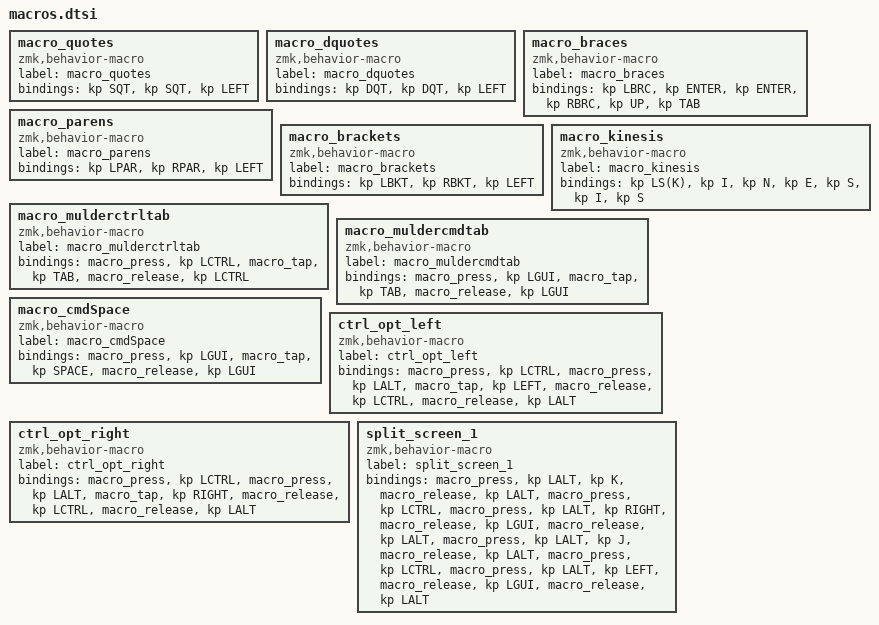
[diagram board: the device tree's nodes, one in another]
  macro_quotes: macro_quotes {
    compatible = "zmk,behavior-macro";
    label = "macro_quotes";
    #binding-cells = <0>;
    bindings = <&kp SQT>, <&kp SQT>, <&kp LEFT>;
  };
  macro_dquotes: macro_dquotes {
    compatible = "zmk,behavior-macro";
    label = "macro_dquotes";
    #binding-cells = <0>;
    bindings = <&kp DQT>, <&kp DQT>, <&kp LEFT>;
  };
  macro_braces: macro_braces {
    compatible = "zmk,behavior-macro";
    label = "macro_braces";
    #binding-cells = <0>;
    bindings = <&kp LBRC>, <&kp ENTER>, <&kp ENTER>, <&kp RBRC>, <&kp UP>, <&kp TAB>;
  };
  macro_parens: macro_parens {
    compatible = "zmk,behavior-macro";
    label = "macro_parens";
    #binding-cells = <0>;
    bindings = <&kp LPAR>, <&kp RPAR>, <&kp LEFT>;
  };
  macro_brackets: macro_brackets {
    compatible = "zmk,behavior-macro";
    label = "macro_brackets";
    #binding-cells = <0>;
    bindings = <&kp LBKT>, <&kp RBKT>, <&kp LEFT>;
  };
  macro_kinesis: macro_kinesis {
    compatible = "zmk,behavior-macro";
    label = "macro_kinesis";
    #binding-cells = <0>;
    bindings = <&kp LS(K)>, <&kp I>, <&kp N>, <&kp E>, <&kp S>, <&kp I>, <&kp S>;
  };
  macro_mulderctrltab: macro_mulderctrltab {
    compatible = "zmk,behavior-macro";
    label = "macro_mulderctrltab";
    #binding-cells = <0>;
    bindings = <&macro_press &kp LCTRL> , <&macro_tap &kp TAB>, <&macro_release &kp LCTRL>;
  };
  macro_muldercmdtab: macro_muldercmdtab {
  compatible = "zmk,behavior-macro";
  label = "macro_muldercmdtab";
  #binding-cells = <0>;
  bindings = <&macro_press &kp LGUI> , <&macro_tap &kp TAB>, <&macro_release &kp LGUI>;
  };
  macro_cmdSpace: macro_cmdSpace {
  compatible = "zmk,behavior-macro";
  label = "macro_cmdSpace";
  #binding-cells = <0>;
  bindings = <&macro_press &kp LGUI> , <&macro_tap &kp SPACE>, <&macro_release &kp LGUI>;
  };

  ctrl_opt_left: ctrl_opt_left  {
    compatible = "zmk,behavior-macro";
    label = "ctrl_opt_left";
    #binding-cells = <0>;
    bindings = <&macro_press &kp LCTRL>, <&macro_press &kp LALT>, <&macro_tap &kp LEFT>, <&macro_release &kp LCTRL>, <&macro_release &kp LALT>;
  };

  ctrl_opt_right: ctrl_opt_right  {
    compatible = "zmk,behavior-macro";
    label = "ctrl_opt_right";
    #binding-cells = <0>;
    bindings = <&macro_press &kp LCTRL>, <&macro_press &kp LALT>, <&macro_tap &kp RIGHT>, <&macro_release &kp LCTRL>, <&macro_release &kp LALT>;
  };

  split_screen_1: split_screen_1 {
    compatible = "zmk,behavior-macro";
    label = "split_screen_1";
    #binding-cells = <0>;
    bindings = <&macro_press &kp LALT>, <&kp K>, <&macro_release &kp LALT>, <&macro_press &kp LCTRL>, <&macro_press &kp LALT>, <&kp RIGHT>, <&macro_release &kp LGUI>, <&macro_release &kp LALT>,<&macro_press &kp LALT>, <&kp J>, <&macro_release &kp LALT>, <&macro_press &kp LCTRL>, <&macro_press &kp LALT>, <&kp LEFT>, <&macro_release &kp LGUI>, <&macro_release &kp LALT>;
  };
